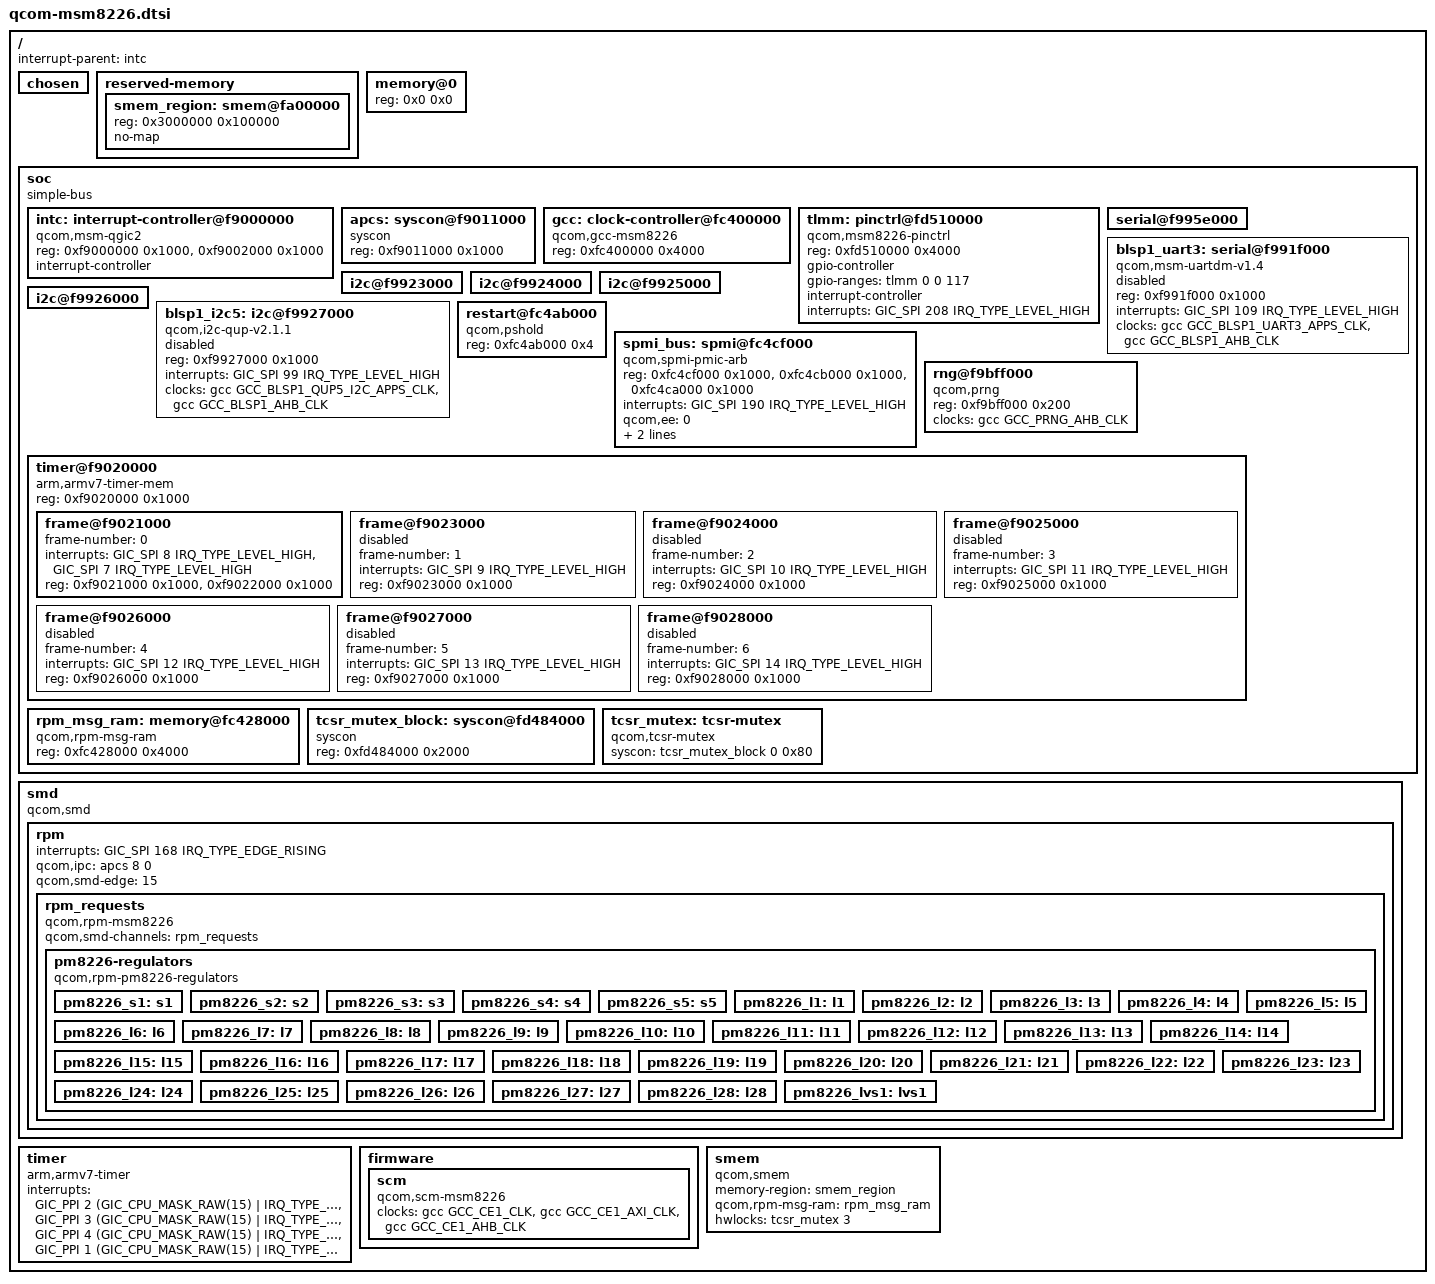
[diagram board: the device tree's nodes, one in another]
// SPDX-License-Identifier: BSD-3-Clause
/*
 * Copyright (c) 2020, The Linux Foundation. All rights reserved.
 */

/dts-v1/;

#include <dt-bindings/interrupt-controller/arm-gic.h>
#include <dt-bindings/clock/qcom,gcc-msm8974.h>

/ {
	#address-cells = <1>;
	#size-cells = <1>;
	interrupt-parent = <&intc>;

	chosen { };

	reserved-memory {
		#address-cells = <1>;
		#size-cells = <1>;
		ranges;

		smem_region: smem@fa00000 {
			reg = <0x3000000 0x100000>;
			no-map;
		};
	};

	memory@0 {
		device_type = "memory";
		reg = <0x0 0x0>;
	};

	soc: soc {
		compatible = "simple-bus";
		#address-cells = <1>;
		#size-cells = <1>;
		ranges;

		intc: interrupt-controller@f9000000 {
			compatible = "qcom,msm-qgic2";
			reg = <0xf9000000 0x1000>,
			      <0xf9002000 0x1000>;
			interrupt-controller;
			#interrupt-cells = <3>;
		};

		apcs: syscon@f9011000 {
			compatible = "syscon";
			reg = <0xf9011000 0x1000>;
		};

		gcc: clock-controller@fc400000 {
			compatible = "qcom,gcc-msm8226";
			reg = <0xfc400000 0x4000>;
			#clock-cells = <1>;
			#reset-cells = <1>;
			#power-domain-cells = <1>;
		};

		tlmm: pinctrl@fd510000 {
			compatible = "qcom,msm8226-pinctrl";
			reg = <0xfd510000 0x4000>;
			gpio-controller;
			#gpio-cells = <2>;
			gpio-ranges = <&tlmm 0 0 117>;
			interrupt-controller;
			#interrupt-cells = <2>;
			interrupts = <GIC_SPI 208 IRQ_TYPE_LEVEL_HIGH>;
		};

		// no BLSP1 UART1 configured?

		/* BLSP1 UART2 */
		serial@f995e000 { /* TODO */ };

		blsp1_uart3: serial@f991f000 {
			compatible = "qcom,msm-uartdm-v1.4", "qcom,msm-uartdm";
			reg = <0xf991f000 0x1000>;
			interrupts = <GIC_SPI 109 IRQ_TYPE_LEVEL_HIGH>;
			clocks = <&gcc GCC_BLSP1_UART3_APPS_CLK>, <&gcc GCC_BLSP1_AHB_CLK>;
			clock-names = "core", "iface";
			status = "disabled";
		};

		/* BLSP1 QUP1 */
		i2c@f9923000 { /* TODO */ };

		/* BLSP1 QUP2 */
		i2c@f9924000 { /* TODO */ };

		/* BLSP1 QUP3 */
		i2c@f9925000 { /* TODO */ };

		/* BLSP1 QUP4 */
		i2c@f9926000 { /* TODO */ };

		/* BLSP1 QUP5 */
		blsp1_i2c5: i2c@f9927000 {
			status = "disabled";
			compatible = "qcom,i2c-qup-v2.1.1";
			reg = <0xf9927000 0x1000>;
			interrupts = <GIC_SPI 99 IRQ_TYPE_LEVEL_HIGH>;
			clocks = <&gcc GCC_BLSP1_QUP5_I2C_APPS_CLK>, <&gcc GCC_BLSP1_AHB_CLK>;
			clock-names = "core", "iface";
			#address-cells = <1>;
			#size-cells = <0>;
		};

		restart@fc4ab000 {
			compatible = "qcom,pshold";
			reg = <0xfc4ab000 0x4>;
		};

		spmi_bus: spmi@fc4cf000 {
			compatible = "qcom,spmi-pmic-arb";
			reg-names = "core", "intr", "cnfg";
			reg = <0xfc4cf000 0x1000>,
			      <0xfc4cb000 0x1000>,
			      <0xfc4ca000 0x1000>;
			interrupt-names = "periph_irq";
			interrupts = <GIC_SPI 190 IRQ_TYPE_LEVEL_HIGH>;
			qcom,ee = <0>;
			qcom,channel = <0>;
			#address-cells = <2>;
			#size-cells = <0>;
			interrupt-controller;
			#interrupt-cells = <4>;
		};

		rng@f9bff000 {
			compatible = "qcom,prng";
			reg = <0xf9bff000 0x200>;
			clocks = <&gcc GCC_PRNG_AHB_CLK>;
			clock-names = "core";
		};

		timer@f9020000 {
			compatible = "arm,armv7-timer-mem";
			reg = <0xf9020000 0x1000>;
			#address-cells = <1>;
			#size-cells = <1>;
			ranges;

			frame@f9021000 {
				frame-number = <0>;
				interrupts = <GIC_SPI 8 IRQ_TYPE_LEVEL_HIGH>,
					     <GIC_SPI 7 IRQ_TYPE_LEVEL_HIGH>;
				reg = <0xf9021000 0x1000>,
				      <0xf9022000 0x1000>;
			};

			frame@f9023000 {
				frame-number = <1>;
				interrupts = <GIC_SPI 9 IRQ_TYPE_LEVEL_HIGH>;
				reg = <0xf9023000 0x1000>;
				status = "disabled";
			};

			frame@f9024000 {
				frame-number = <2>;
				interrupts = <GIC_SPI 10 IRQ_TYPE_LEVEL_HIGH>;
				reg = <0xf9024000 0x1000>;
				status = "disabled";
			};

			frame@f9025000 {
				frame-number = <3>;
				interrupts = <GIC_SPI 11 IRQ_TYPE_LEVEL_HIGH>;
				reg = <0xf9025000 0x1000>;
				status = "disabled";
			};

			frame@f9026000 {
				frame-number = <4>;
				interrupts = <GIC_SPI 12 IRQ_TYPE_LEVEL_HIGH>;
				reg = <0xf9026000 0x1000>;
				status = "disabled";
			};

			frame@f9027000 {
				frame-number = <5>;
				interrupts = <GIC_SPI 13 IRQ_TYPE_LEVEL_HIGH>;
				reg = <0xf9027000 0x1000>;
				status = "disabled";
			};

			frame@f9028000 {
				frame-number = <6>;
				interrupts = <GIC_SPI 14 IRQ_TYPE_LEVEL_HIGH>;
				reg = <0xf9028000 0x1000>;
				status = "disabled";
			};
		};

		rpm_msg_ram: memory@fc428000 {
			compatible = "qcom,rpm-msg-ram";
			reg = <0xfc428000 0x4000>;
		};

		tcsr_mutex_block: syscon@fd484000 {
			compatible = "syscon";
			reg = <0xfd484000 0x2000>;
		};

		tcsr_mutex: tcsr-mutex {
			compatible = "qcom,tcsr-mutex";
			syscon = <&tcsr_mutex_block 0 0x80>;

			#hwlock-cells = <1>;
		};
	};

	smd {
		compatible = "qcom,smd";

		rpm {
			interrupts = <GIC_SPI 168 IRQ_TYPE_EDGE_RISING>;
			qcom,ipc = <&apcs 8 0>;
			qcom,smd-edge = <15>;

			rpm_requests {
				compatible = "qcom,rpm-msm8226";
				qcom,smd-channels = "rpm_requests";

				pm8226-regulators {
					compatible = "qcom,rpm-pm8226-regulators";

					pm8226_s1: s1 {};
					pm8226_s2: s2 {};
					pm8226_s3: s3 {};
					pm8226_s4: s4 {};
					pm8226_s5: s5 {};

					pm8226_l1: l1 {};
					pm8226_l2: l2 {};
					pm8226_l3: l3 {};
					pm8226_l4: l4 {};
					pm8226_l5: l5 {};
					pm8226_l6: l6 {};
					pm8226_l7: l7 {};
					pm8226_l8: l8 {};
					pm8226_l9: l9 {};
					pm8226_l10: l10 {};
					pm8226_l11: l11 {};
					pm8226_l12: l12 {};
					pm8226_l13: l13 {};
					pm8226_l14: l14 {};
					pm8226_l15: l15 {};
					pm8226_l16: l16 {};
					pm8226_l17: l17 {};
					pm8226_l18: l18 {};
					pm8226_l19: l19 {};
					pm8226_l20: l20 {};
					pm8226_l21: l21 {};
					pm8226_l22: l22 {};
					pm8226_l23: l23 {};
					pm8226_l24: l24 {};
					pm8226_l25: l25 {};
					pm8226_l26: l26 {};
					pm8226_l27: l27 {};
					pm8226_l28: l28 {};

					pm8226_lvs1: lvs1 {};
				};
			};
		};
	};

	timer {
		compatible = "arm,armv7-timer";
		interrupts = <GIC_PPI 2
				(GIC_CPU_MASK_RAW(15) | IRQ_TYPE_LEVEL_LOW)>,
			     <GIC_PPI 3
				(GIC_CPU_MASK_RAW(15) | IRQ_TYPE_LEVEL_LOW)>,
			     <GIC_PPI 4
				(GIC_CPU_MASK_RAW(15) | IRQ_TYPE_LEVEL_LOW)>,
			     <GIC_PPI 1
				(GIC_CPU_MASK_RAW(15) | IRQ_TYPE_LEVEL_LOW)>;
	};

	firmware {
		scm {
			compatible = "qcom,scm-msm8226", "qcom,scm";
			clocks = <&gcc GCC_CE1_CLK>, <&gcc GCC_CE1_AXI_CLK>, <&gcc GCC_CE1_AHB_CLK>;
			clock-names = "core", "bus", "iface";
		};
	};

	smem {
		compatible = "qcom,smem";

		memory-region = <&smem_region>;
		qcom,rpm-msg-ram = <&rpm_msg_ram>;

		hwlocks = <&tcsr_mutex 3>;
	};

};
